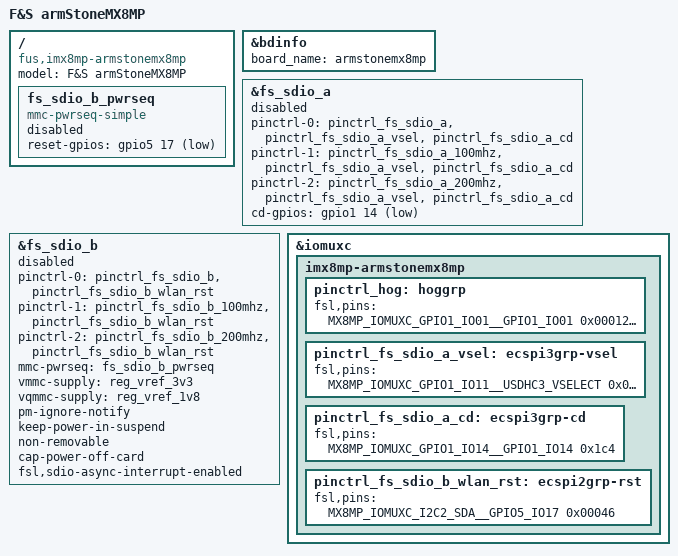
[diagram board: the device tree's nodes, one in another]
#include "armstonemx8mp-common.dtsi"

/ {
	model = "F&S armStoneMX8MP";
	compatible = "fus,imx8mp-armstonemx8mp", "fsl,imx8mp";

	fs_sdio_b_pwrseq: fs_sdio_b_pwrseq {
		compatible = "mmc-pwrseq-simple";
		reset-gpios = <&gpio5 17 GPIO_ACTIVE_LOW>;
		status = "disabled";
	};
};

&bdinfo {
	board_name = "armstonemx8mp";
};

&fs_sdio_a {
	pinctrl-names = "default", "state_100mhz", "state_200mhz";
	pinctrl-0 = <&pinctrl_fs_sdio_a &pinctrl_fs_sdio_a_vsel &pinctrl_fs_sdio_a_cd>;
	pinctrl-1 = <&pinctrl_fs_sdio_a_100mhz &pinctrl_fs_sdio_a_vsel &pinctrl_fs_sdio_a_cd>;
	pinctrl-2 = <&pinctrl_fs_sdio_a_200mhz &pinctrl_fs_sdio_a_vsel &pinctrl_fs_sdio_a_cd>;
	cd-gpios = <&gpio1 14 GPIO_ACTIVE_LOW>;
	status = "disabled";
};

&fs_sdio_b {
	pinctrl-names = "default", "state_100mhz", "state_200mhz";
	pinctrl-0 = <&pinctrl_fs_sdio_b &pinctrl_fs_sdio_b_wlan_rst>;
	pinctrl-1 = <&pinctrl_fs_sdio_b_100mhz &pinctrl_fs_sdio_b_wlan_rst>;
	pinctrl-2 = <&pinctrl_fs_sdio_b_200mhz &pinctrl_fs_sdio_b_wlan_rst>;
	mmc-pwrseq = <&fs_sdio_b_pwrseq>;
	vmmc-supply = <&reg_vref_3v3>;
	vqmmc-supply = <&reg_vref_1v8>;
	pm-ignore-notify;
	keep-power-in-suspend;
	non-removable;
	cap-power-off-card;
	fsl,sdio-async-interrupt-enabled;
	status = "disabled";
};

&iomuxc {
	imx8mp-armstonemx8mp {
		pinctrl_hog: hoggrp {
			fsl,pins = <
				/* SE050_ENA */
				MX8MP_IOMUXC_GPIO1_IO01__GPIO1_IO01			0x00012
				/* SHDN_RS232 */
				MX8MP_IOMUXC_GPIO1_IO03__GPIO1_IO03			0x00142
				/* AUTONLINE_RS232 */
				MX8MP_IOMUXC_GPIO1_IO04__GPIO1_IO04			0x00142
			>;
		};

		pinctrl_fs_sdio_a_vsel: ecspi3grp-vsel {
			fsl,pins = < MX8MP_IOMUXC_GPIO1_IO11__USDHC3_VSELECT	0x0c1>;
		};

		pinctrl_fs_sdio_a_cd: ecspi3grp-cd {
			fsl,pins = <MX8MP_IOMUXC_GPIO1_IO14__GPIO1_IO14	0x1c4>;
		};

		pinctrl_fs_sdio_b_wlan_rst: ecspi2grp-rst {
			fsl,pins = <MX8MP_IOMUXC_I2C2_SDA__GPIO5_IO17	0x00046>;
		};
	};
};
